# STM32F446 register map
File version: 1.9
CPU: CM4 r0p1, little endian, MPU, FPU, 4 interrupt priority bits
Registers are 32-bit, read-write, reset 0x0 unless marked. A register's access mark holds for its fields unless they carry their own. Offsets are from the block's base; [hi:lo] are bit positions; {n}, {i} and the like mark numbered series; 'fields as' and 'values as' point back to an identical list.

## OTG_FS_HOST — USB on the go full speed
Base 0x50000400
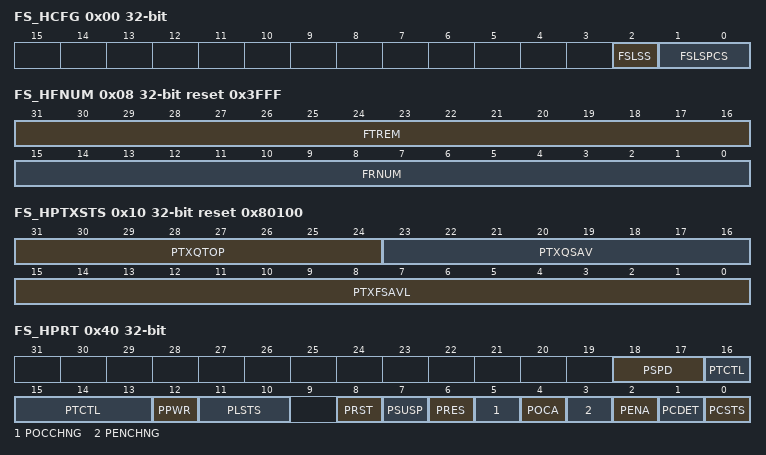
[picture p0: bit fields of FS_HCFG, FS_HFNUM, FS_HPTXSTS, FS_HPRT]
0x00 FS_HCFG access per field — OTG_FS host configuration register (OTG_FS_HCFG)
  [2] FSLSS ro — FS- and LS-only support
  [1:0] FSLSPCS rw — FS/LS PHY clock select
0x04 HFIR reset 0xEA60 — OTG_FS Host frame interval register
  [15:0] FRIVL — Frame interval
0x08 FS_HFNUM ro reset 0x3FFF — OTG_FS host frame number/frame time remaining register (OTG_FS_HFNUM)
  [31:16] FTREM — Frame time remaining
  [15:0] FRNUM — Frame number
0x10 FS_HPTXSTS access per field reset 0x80100 — OTG_FS_Host periodic transmit FIFO/queue status register (OTG_FS_HPTXSTS)
  [31:24] PTXQTOP ro — Top of the periodic transmit request queue
  [23:16] PTXQSAV ro — Periodic transmit request queue space available
  [15:0] PTXFSAVL rw — Periodic transmit data FIFO space available
0x14 HAINT ro — OTG_FS Host all channels interrupt register
  [15:0] HAINT — Channel interrupts
0x18 HAINTMSK — OTG_FS host all channels interrupt mask register
  [15:0] HAINTM — Channel interrupt mask
0x40 FS_HPRT access per field — OTG_FS host port control and status register (OTG_FS_HPRT)
  [18:17] PSPD ro — Port speed
  [16:13] PTCTL rw — Port test control
  [12] PPWR rw — Port power
  [11:10] PLSTS ro — Port line status
  [8] PRST rw — Port reset
  [7] PSUSP rw — Port suspend
  [6] PRES rw — Port resume
  [5] POCCHNG rw — Port overcurrent change
  [4] POCA ro — Port overcurrent active
  [3] PENCHNG rw — Port enable/disable change
  [2] PENA rw — Port enable
  [1] PCDET rw — Port connect detected
  [0] PCSTS ro — Port connect status
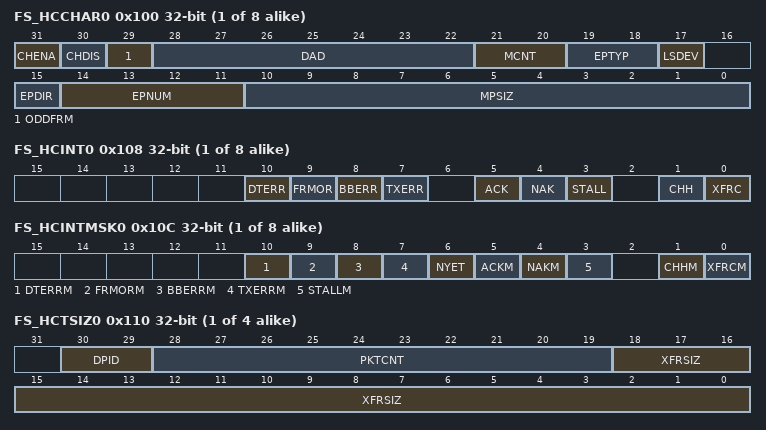
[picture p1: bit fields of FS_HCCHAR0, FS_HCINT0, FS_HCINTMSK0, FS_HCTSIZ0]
{0x100+0x20*i} FS_HCCHAR{i} (i=0..7) — OTG_FS host channel-{i} characteristics register (OTG_FS_HCCHAR{i})
  [31] CHENA — Channel enable
  [30] CHDIS — Channel disable
  [29] ODDFRM — Odd frame
  [28:22] DAD — Device address
  [21:20] MCNT — Multicount
  [19:18] EPTYP — Endpoint type
  [17] LSDEV — Low-speed device
  [15] EPDIR — Endpoint direction
  [14:11] EPNUM — Endpoint number
  [10:0] MPSIZ — Maximum packet size
{0x108+0x20*i} FS_HCINT{i} (i=0..7) — OTG_FS host channel-{i} interrupt register (OTG_FS_HCINT{i})
  [10] DTERR — Data toggle error
  [9] FRMOR — Frame overrun
  [8] BBERR — Babble error
  [7] TXERR — Transaction error
  [5] ACK — ACK response received/transmitted interrupt
  [4] NAK — NAK response received interrupt
  [3] STALL — STALL response received interrupt
  [1] CHH — Channel halted
  [0] XFRC — Transfer completed
{0x10C+0x20*i} FS_HCINTMSK{i} (i=0..7) — OTG_FS host channel-{i} mask register (OTG_FS_HCINTMSK{i})
  [10] DTERRM — Data toggle error mask
  [9] FRMORM — Frame overrun mask
  [8] BBERRM — Babble error mask
  [7] TXERRM — Transaction error mask
  [6] NYET — response received interrupt mask
  [5] ACKM — ACK response received/transmitted interrupt mask
  [4] NAKM — NAK response received interrupt mask
  [3] STALLM — STALL response received interrupt mask
  [1] CHHM — Channel halted mask
  [0] XFRCM — Transfer completed mask
{0x110+0x20*i} FS_HCTSIZ{i} (i=0..3) — OTG_FS host channel-{i} transfer size register
  [30:29] DPID — Data PID
  [28:19] PKTCNT — Packet count
  [18:0] XFRSIZ — Transfer size
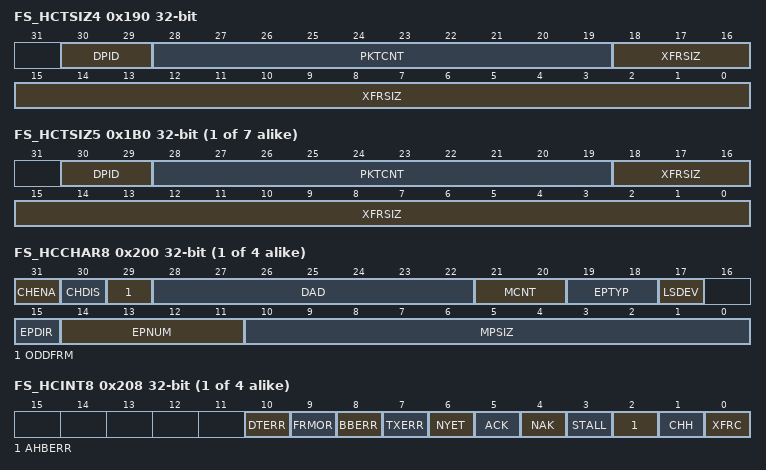
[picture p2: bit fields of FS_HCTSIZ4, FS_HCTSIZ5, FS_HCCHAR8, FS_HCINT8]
0x190 FS_HCTSIZ4 — OTG_FS host channel-x transfer size register
  fields as FS_HCTSIZ0
{0x110+0x20*i} FS_HCTSIZ{i} (i=5..11) — OTG_FS host channel-{i} transfer size register
  fields as FS_HCTSIZ0
{0x100+0x20*i} FS_HCCHAR{i} (i=8..11) — OTG_FS host channel-{i} characteristics register
  [31] CHENA — Channel enable
  [30] CHDIS — Channel disable
  [29] ODDFRM — Odd frame
  [28:22] DAD — Device address
  [21:20] MCNT — Multi Count (MC) / Error Count (EC)
  [19:18] EPTYP — Endpoint type
  [17] LSDEV — Low-speed device
  [15] EPDIR — Endpoint direction
  [14:11] EPNUM — Endpoint number
  [10:0] MPSIZ — Maximum packet size
{0x108+0x20*i} FS_HCINT{i} (i=8..11) — OTG_FS host channel-{i} interrupt register
  [10] DTERR — Data toggle error
  [9] FRMOR — Frame overrun
  [8] BBERR — Babble error
  [7] TXERR — Transaction error
  [6] NYET — Response received interrupt
  [5] ACK — ACK response received/transmitted interrupt
  [4] NAK — NAK response received interrupt
  [3] STALL — STALL response received interrupt
  [2] AHBERR — AHB error
  [1] CHH — Channel halted
  [0] XFRC — Transfer completed
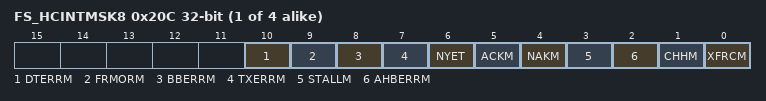
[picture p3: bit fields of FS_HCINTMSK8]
{0x10C+0x20*i} FS_HCINTMSK{i} (i=8..11) — OTG_FS host channel-{i} interrupt mask register
  [10] DTERRM — Data toggle error mask
  [9] FRMORM — Frame overrun mask
  [8] BBERRM — Babble error mask
  [7] TXERRM — Transaction error mask
  [6] NYET — response received interrupt mask
  [5] ACKM — ACK response received/transmitted interrupt mask
  [4] NAKM — NAK response received interrupt mask
  [3] STALLM — STALL response received interrupt mask
  [2] AHBERRM — AHB error
  [1] CHHM — Channel halted mask
  [0] XFRCM — Transfer completed mask

## Notices in the file
Copyright (c) 2024 STMicroelectronics.
SPDX-License-Identifier: Apache-2.0
Licensed under the Apache License, Version 2.0 (the "License");
you may not use this file except in compliance with the License.
You may obtain a copy of the License at
http://www.apache.org/licenses/LICENSE-2.0
Unless required by applicable law or agreed to in writing, software
distributed under the License is distributed on an "AS IS" BASIS,
WITHOUT WARRANTIES OR CONDITIONS OF ANY KIND, either express or implied.
See the License for the specific language governing permissions and
limitations under the License.
